# RL6845_IP_SVD register map
Vendor: Realtek
Registers are 32-bit, read-write, reset 0x0 unless marked. A register's access mark holds for its fields unless they carry their own. Offsets are from the block's base; [hi:lo] are bit positions; lines under a group give offsets from that group; {n}, {i} and the like mark numbered series; <NAME> marks a mode.

## lp_sys
Base 0x41008200
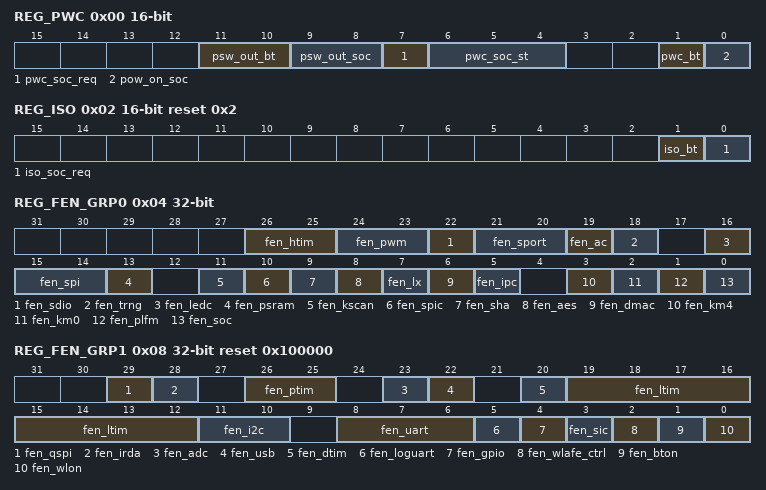
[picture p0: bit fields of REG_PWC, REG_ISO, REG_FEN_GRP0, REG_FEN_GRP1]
0x00 REG_PWC 16-bit access per field
  [11:10] psw_out_bt ro — BT domain power switch status 1: power on 0: power off Note:there are two group
  [9:8] psw_out_soc ro — SOC domain power switch status 1: power on 0: power off Note:there are two group
  [7] pwc_soc_req ro — pwc soc req arb result
  [6:4] pwc_soc_st ro — pwc soc arb result state
  [1] pwc_bt rw — This is BT function total power cut control 1: Enable BT power cut 0: Disable
  [0] pow_on_soc rw — 1:SYS PMC request to enable HP SOC power cut and diable ISO 0: SYS PMC request to disable HP SOC power cut and enable ISO
0x02 REG_ISO 16-bit access per field reset 0x2
  [1] iso_bt rw — 1: isolate signals from PD_LP_BT to other power domain 0: release iso
  [0] iso_soc_req ro — isolate signals from PD_HP_SOC to other power domain. It is arb result
0x04 REG_FEN_GRP0
  [26:25] fen_htim — 1: enable TIMER 14 function 0: disable
  [24:23] fen_pwm — 1: enable PWM TIMER function 0: disable [1]:pwm [0]:pulse
  [22] fen_sdio — 1: enable sdio device function 0: disable
  [21:20] fen_sport — 1: enable SPORT function 0: disable
  [19] fen_ac — 1: enable audio codec digital ip active function 0: disable
  [18] fen_trng — 1: enable TRNG function 0: disable
  [16] fen_ledc — 1: enable LEDC function 0: disable
  [15:14] fen_spi — 1: enable SPI1 function 0: disable
  [13] fen_psram — 1: enable PSRAM function 0: disable
  [11] fen_kscan — Flash kscan function enable 1: enable sce 0: disable
  [10] fen_spic — Flash spic function enable 1: enable flash 0: disable flash
  [9] fen_sha — 1: enable IPSEC SHA function 0: disable
  [8] fen_aes — 1: enable IPSEC AES function 0: disable
  [7] fen_lx — 1: enable LX1 system function 0: disable
  [6] fen_dmac — 1: enable GDMA function 0: disable
  [5] fen_ipc — 1: enable IPC function 0: reset
  [3] fen_km4 — 1: enable KM4 0: reset
  [2] fen_km0 — 1: enable KM0 0: reset
  [1] fen_plfm — 1: enable platform 0: reset
  [0] fen_soc — 1: enable hs soc sytem 0: disable hs soc system (Note: used as soc power on reset)
0x08 REG_FEN_GRP1 reset 0x100000
  [29] fen_qspi — 1: enable qspi function 0: disable
  [28] fen_irda — 1: enable irda function 0: disable
  [26:25] fen_ptim — pmc_timer function enable 1: enable 0: disable
  [23] fen_adc — lp adc function enable 1: enable 0: disable
  [22] fen_usb — usb core function enable 1: enable 0: disable
  [20] fen_dtim — Debug timer function enable 1: enable 0: disable
  [19:12] fen_ltim — Basic Timer0-7 function enable 1: enable 0: disable
  [11:10] fen_i2c — I2C1 function enable 1: enable 0: disable
  [8:6] fen_uart — Uart function enable (Note uart2 if for BT) 1: enable 0: disable
  [5] fen_loguart — Uartlog function enable 1: enable 0: disable
  [4] fen_gpio — SGPIO function enable 1: enable 0: disable
  [3] fen_sic — 1: enable SIC function 0: reset
  [2] fen_wlafe_ctrl — WL RFAFE control function enable 1: enable 0: disable
  [1] fen_bton — BTON function enable 1: enable 0: disable
  [0] fen_wlon — WLON function enable 1: enable 0: disable
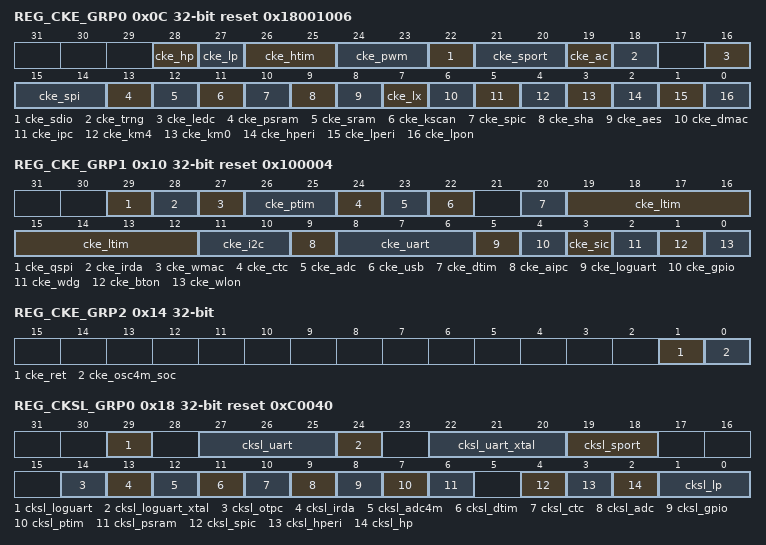
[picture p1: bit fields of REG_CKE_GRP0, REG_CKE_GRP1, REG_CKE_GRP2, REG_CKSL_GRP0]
0x0C REG_CKE_GRP0 reset 0x18001006
  [28] cke_hp — 1: Enable HP clock 0: Disable
  [27] cke_lp — 1: Enable LP clock 0: Disable
  [26:25] cke_htim — 1: Enable HS basic TIMER clock 0: Disable
  [24:23] cke_pwm — 1: Enable PWM TIMER clock 0: Disable [1] : pwm timer [0] : pulse timer
  [22] cke_sdio — 1: Enable sdio clock 0: Disable
  [21:20] cke_sport — 1: Enable sport1 clock 0: Disable
  [19] cke_ac — 1: Enable audio codec clock 0: Disable
  [18] cke_trng — 1: Enable trng bus clock 0: Disable
  [16] cke_ledc — 1: Enable ledc bus clock 0: Disable
  [15:14] cke_spi — 1: Enable SPI1 clock 0: Disable
  [13] cke_psram — 1: Enable PSRAM bus clock 0: Disable
  [12] cke_sram — 1: Enable hp sram clock 0: Disable
  [11] cke_kscan — 1: Enable kscan clock
  [10] cke_spic — 1: Enable SPIC source clock
  [9] cke_sha — 1: Enable ipsec SHA clock 0: Disable
  [8] cke_aes — 1: Enable ipsec AES clock 0: Disable
  [7] cke_lx — 1: Enable lx1 bus clock 0: Disable
  [6] cke_dmac — 1: Enable GDMA0 clock 0: Disable
  [5] cke_ipc — 1: Enable IPC clock 0: Disable
  [4] cke_km4 — 1: Enable hp KM4 clock 0: Disable
  [3] cke_km0 — 1: Enable lp KM0 clock 0: Disable
  [2] cke_hperi — 1: Enable peri_hclk clock all 0: Disable
  [1] cke_lperi — 1: Enable peri_lclk clock all 0: Disable
  [0] cke_lpon — 1.Enable lpon clk 0: Disable Note: this bit is controlled HW PMC, SW shall not modify
0x10 REG_CKE_GRP1 reset 0x100004
  [29] cke_qspi — 1: Enable qsip clock 0: Disable
  [28] cke_irda — 1: Enable irda clock 0: Disable
  [27] cke_wmac — 1: Enable WMAC AXI and AHB bus clock 0: Disable
  [26:25] cke_ptim — 1: Enable pmc timer clock 0: Disable
  [24] cke_ctc — 1: Enable Captouch clock 0: Disable
  [23] cke_adc — 1: Enable LS ADC clock 0: Disable
  [22] cke_usb — 1: Enable usb core clock 0: Disable
  [20] cke_dtim — 1: Enable LS dtim clk 0: Disable
  [19:12] cke_ltim — LS basic Timer0-7 clk enable 0: Disable
  [11:10] cke_i2c — 1: Enable HS I2C0 clock 0: Disable [1]: i2c1 [0]: i2c0
  [9] cke_aipc — 1: Enable aipc clock 0: Disable Note:HW has auto-gating function , sw needn't set it unless hw failed
  [8:6] cke_uart — 1: Enable Uart clock 0: Disable
  [5] cke_loguart — 1: Enable Uartlog clock 0: Disable
  [4] cke_gpio — 1: Enable GPIO clock 0: Disable
  [3] cke_sic — 1: Enable SIC clock 0: Disable
  [2] cke_wdg — 1: Enable wdg bus clock 0: Disable
  [1] cke_bton — 1: Enable BTON clock 0: Disable
  [0] cke_wlon — 1: Enable WLON clock 0: Disable
0x14 REG_CKE_GRP2
  [1] cke_ret — 1.Enable Some IP's clock who has retention function when pmc state change 0: Disable Note: this bit is controlled HW PMC, SW shall not modify
  [0] cke_osc4m_soc — 1.Enable 4M clk path for soc clk 0: Disable Note: this bit is controlled HW PMC, SW shall not modify
0x18 REG_CKSL_GRP0 reset 0xC0040
  [29] cksl_loguart — Select div_loguart's input clock (div_loguart's output clock is loguart trx clock ) 0: clock is xtal(source is dicided by cksl_loguart_xtal) 1: clock is osc4M
  [27:25] cksl_uart — Select div_uart[n]'s input clock (div_uart[n]'s output clock is uart[n] rx clock). (n=0,1,2) 0: clock is xtal(source is dicided by cksl_uart_xtal) 1: clock is osc4M
  [24] cksl_loguart_xtal — loguart_xtal clk select 0:clk_xtal_digi 1:clk_xtal_digi_div2
  [22:20] cksl_uart_xtal — uart xtal clk select, cksl_uart_xtal[n](n=0,1,2) 0: clk_xtal_digi 1:clk_xtal_digi_div2
  [19:18] cksl_sport — sport clock selection 0: equal to audio codec main clock (40M) 1: from cpu/dsp pll , after pll selection(cksl_i2s_pll)
  [14] cksl_otpc — otpc clock selection 0: osc4m 1: xtal40m Note: this bit will be set by pmc auto, when SW use otp, it must be set to 1 already
  [13] cksl_irda — IRDA clock selection 0: xtal 40m 1: pll divider out
  [12] cksl_adc4m — lp adc 4m clk selection 0: from osc4m 1: divider from xtal
  [11] cksl_dtim — dtim clock selection 0: xtal 1: 32k for sleep
  [10] cksl_ctc — CTC REG clock selection 0: lbus clock 1: ctc ip clock
  [9] cksl_adc — ADC INT clock selection 0: lbus clock 1: adc ip clock
  [8] cksl_gpio — GPIO INT clock selecton: 0: lbus clock 1: 32.768K clock from SDM
  [7] cksl_ptim — PMC Timer INT clock selecton: 0: lbus clock 1: 32.768K clock from SDM
  [6] cksl_psram — psram clock select 0: xtal 40m 1: pll divider out
  [4] cksl_spic — spic clock select 0: xtal 40m 1: pll divider out
  [3] cksl_hperi — hperi clock seletion 0: xtal 40m 1: pll divider out
  [2] cksl_hp — HP clock select,used for KM4 and sram 0: xtal 40m 1: pll divider out
  [1:0] cksl_lp — LP clock select, used for KM0 0: osc4m 1: xtal_40m 2: NotValid 3: pll divider out
0x1C REG_CKSL_GRP1
  [3:0] cksl_xtal — xtal selection, Default=40MHz No use,only support 40M
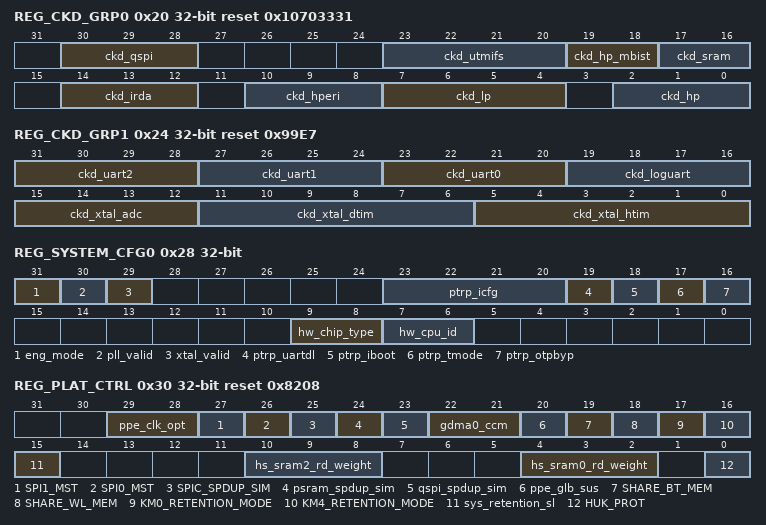
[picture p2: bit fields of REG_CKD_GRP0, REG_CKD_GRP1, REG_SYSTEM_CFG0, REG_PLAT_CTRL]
0x20 REG_CKD_GRP0 reset 0x10703331
  [30:28] ckd_qspi — qspi clock divider, it is based on pll 0: div1 1: div2 2: div3 3/other: divider by this value + 1
  [23:20] ckd_utmifs — usb full-speed 48M clock divider, it is based on cpu pll output 0: not valid 1: div2 2: div3 3/other: divider by this value + 1
  [19:18] ckd_hp_mbist — hp(km4) clock divider, it is based on pll 0: div1 1: div2 2: div3 3/other: divider by this value + 1 Note: this divider just for HW mbist test , SW don't use it
  [17:16] ckd_sram — sram clock divider, it is based on hp_clk 0: div1 1: div2 2: div3 3/other: divider by this value + 1
  [14:12] ckd_irda — irda clock divider, it is based on sys pll 0 : not valid 1: div2 2: div3 3/other: divider by this value + 1
  [10:8] ckd_hperi — peri_hclk clock divider, it is based on sys pll 0 : not valid 1: div2 2: div3 3/other: divider by this value + 1
  [7:4] ckd_lp — KM0 pll clock divider 0: div1 1: div2 2: div3 3/other: divider by this value + 1
  [2:0] ckd_hp — hp(km4) clock divider, it is based on pll 0: div1 1: div2 2: div3 3/other: divider by this value + 1
0x24 REG_CKD_GRP1 reset 0x99E7
  [31:28] ckd_uart2 — uart2 rx divider, source select by cksl_uart N:divider by N+1 1:divider by 2 0:divider by 1 Note: If uart need lps wake up when using xtal source , divider must set to 9 , and using xtal_20M input,when using OSC4M source , divider must set 1. (it is constrained by STA)
  [27:24] ckd_uart1 — uart1 rx divider, source select by cksl_uart N:divider by N+1 1:divider by 2 0:divider by 1 Note: If uart need lps wake up when using xtal source , divider must set to 9 , and using xtal_20M input,when using OSC4M source , divider must set 1. (it is constrained by STA)
  [23:20] ckd_uart0 — uart0 rx divider, source select by cksl_uart N:divider by N+1 1:divider by 2 0:divider by 1 Note: If uart need lps wake up when using xtal source , divider must set to 9 , and using xtal_20M input,when using OSC4M source , divider must set 1. (it is constrained by STA)
  [19:16] ckd_loguart — loguart rx divider, source select by cksl_uart N:divider by N+1 1:divider by 2 0:divider by 1 Note: If uart need lps wake up when using xtal source , divider must set to 9 , and using xtal_20M input,when using OSC4M source , divider must set 1. (it is constrained by STA)
  [15:12] ckd_xtal_adc — xtal 4m divider for adc Default is /10 which output 4M
  [11:6] ckd_xtal_dtim — xtal 1m divider for dtim Default is /40 which output 4M
  [5:0] ckd_xtal_htim — xtal 1m divider for htim Default is /40 which output 4M
0x28 REG_SYSTEM_CFG0 ro
  [31] eng_mode — Indicate PKG_ENG_SEL pad value 0: normal package; 1: engineering mode
  [30] pll_valid — Indicator pll is ready
  [29] xtal_valid — Indicator xtal 40M is ready
  [23:20] ptrp_icfg — Trapped ICFG data value 0: normall mode XXXX: the other mode (Test Mode)
  [19] ptrp_uartdl — Power on trapped uart download value 0: Normal boot 1: uartdownload boot TODO: it may be overwrited by efuse autoload
  [18] ptrp_iboot — Internal or external flash boot select
  [17] ptrp_tmode — 0: normal mode 1: test mode
  [16] ptrp_otpbyp — 1: force efuse autoload fail
  [9:8] hw_chip_type — Chip type 00: ASIC 01: FPGA 10: PALADIUM 11: RTL_SIM
  [7:6] hw_cpu_id — Different CPU reading this register will return different value. If read by KM0: return 0 If read by KM4: return 1 Other will return 2
0x30 REG_PLAT_CTRL reset 0x8208
  [29:28] ppe_clk_opt — 1X: always ON 01: always OFF 00: controlled by internal ICG
  [27] SPI1_MST — 1: SPI1 used as master 0: SPI1 used as slaver
  [26] SPI0_MST — 1: SPI0 used as master 0: SPI0 used as slaver
  [25] SPIC_SPDUP_SIM — 1: SPIC will wait 256 spic_clk cycles before ready 0: SPIC will wait 2^16 spic_clk cycles before ready
  [24] psram_spdup_sim — psramc simulatin speedup enable. Nouse because config form not specified .
  [23] qspi_spdup_sim — qspi simulation speedup enable
  [22:21] gdma0_ccm — GDMA0 clock control mode
  [20] ppe_glb_sus — Assert this bit to suspend PPE, active high
  [19] SHARE_BT_MEM — 1: Enable KM4 to share BT memory
  [18] SHARE_WL_MEM — 1: Enable KM4 to share WL memory
  [17] KM0_RETENTION_MODE — 1: Enable, when KM0 reset, cache will not be cleared 0: Disable, when KM0 reset, cache will be cleared by HW
  [16] KM4_RETENTION_MODE — 1: Enable, when KM4 reset, cache will not be cleared 0: Disable, when KM4 reset, cache will be cleared by HW
  [15] sys_retention_sl — S/L control signal to retention DFFs at PD_SOC, direct to SL pin, default 1 to prevent leakage 0: normal mode 1: retention data 1->0: restore data
  [10:8] hs_sram2_rd_weight — Excuted read command number continuously if both read and write command reached This is for bt/wl share_ram
  [4:2] hs_sram0_rd_weight — Excuted read command number continuously if both read and write command reached This is for hs_ram 512K
  [0] HUK_PROT — 0: only cpu can read HUK key 1: no one can read HUK key This bit will be latch to high when it was write to 1 until reset again .
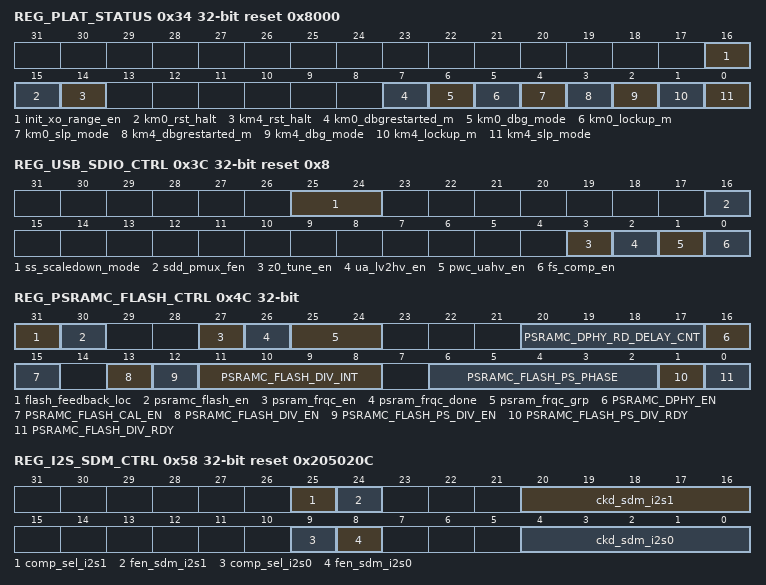
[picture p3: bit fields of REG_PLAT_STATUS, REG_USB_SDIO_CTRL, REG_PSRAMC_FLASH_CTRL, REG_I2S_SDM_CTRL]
0x34 REG_PLAT_STATUS access per field reset 0x8000
  [16] init_xo_range_en rw
  [15] km0_rst_halt rw
  [14] km4_rst_halt rw
  [7] km0_dbgrestarted_m ro — KM0 debug restart status
  [6] km0_dbg_mode ro — KM0 debug status
  [5] km0_lockup_m ro — KM0 lockup status
  [4] km0_slp_mode ro — KM0 sleep status
  [3] km4_dbgrestarted_m ro — KM4 debug restart status
  [2] km4_dbg_mode ro — KM4 halt status
  [1] km4_lockup_m ro — KM4 lockup status
  [0] km4_slp_mode ro — KM4 sleep status
0x3C REG_USB_SDIO_CTRL reset 0x8
  [25:24] ss_scaledown_mode — use scaled-down timing values for usb, resulting in faster simulations
  [16] sdd_pmux_fen — after sdio pinmux is configured, set this bit to 1
  [3] z0_tune_en — Zo_Tune , 45Ωauto calibration(Port-1 only) 0: Zo_Tune disable 1: Zo_Tune enable
  [2] ua_lv2hv_en — enable usb comparator l2h level shifter
  [1] pwc_uahv_en — enable usb comparator 3.3v power cut
  [0] fs_comp_en — enable usb full-speed differential comparator
0x40 REG_KM4_XO_CTRL0
  [31:0] init_xo_base
0x44 REG_KM4_XO_CTRL1
  [31:0] init_xo_top
0x4C REG_PSRAMC_FLASH_CTRL access per field
  [31] flash_feedback_loc rw — 0: pinmux S0 -> flash_spic, pinmux S1 -> psram_spic(if psramc_flash_en) 1: pinmux S1 -> flash_spic, pinmux S0 -> psram_spic(if psramc_flash_en)
  [30] psramc_flash_en rw — use psram_spic as flash controller, disable psram_phy
  [27] psram_frqc_en rw — enable psram auto freq change control flow
  [26] psram_frqc_done ro — indicate psram auto freq change is done
  [25:24] psram_frqc_grp rw — select psram auto freq change group
  [20:17] PSRAMC_DPHY_RD_DELAY_CNT rw — spic_dphy output dealy cnt, when set < 3, output data will occur at fourth or fifth axi clock from the rising edge of spi_rx_data_en; when set >= 3, data will occur after DPHY_RD_DELAY_CNT + 2 axi clock from the rising edge of spi_rx_data_en
  [16] PSRAMC_DPHY_EN rw — when set, enable spic_dphy function to read data from flash
  [15] PSRAMC_FLASH_CAL_EN rw — Flash calibration enable 1: delay flash sout for calibration 0: bypass flash sout to spic
  [13] PSRAMC_FLASH_DIV_EN rw — 1: enable to generate flash clock (no phase shift) divided by 600M pll clock, HW detect this signal's rising edge to start the no phase shift division circuit.
  [12] PSRAMC_FLASH_PS_DIV_EN rw — 1: enable to generate flash clock (with phase shift) divided by 600M pll clock, HW detect this signal's rising edge to start the phase shift clock division circuit.
  [11:8] PSRAMC_FLASH_DIV_INT rw — Flash clock division ratio, integrate part 0: divided by 1 1: divided by 2 2: divided by 3 3: divided by 4 .. 7: divided by 8 8: divided by 9 9: divided by 10 Note: SPI clock frequency is this divided clock/2
  [6:2] PSRAMC_FLASH_PS_PHASE rw — Flash clock phase shift in units of cpu/dsp pll clock cycles. If selected pll is 500MHz, the step is 2ns. 0: shift 0 step 1: shift 1 step ... 19: shift 19 step. Note, this value cannot be set more than FLASH_DIV_INT
  [1] PSRAMC_FLASH_PS_DIV_RDY ro — Ready flag of Flash clock with phase shift, Read only (input signal)
  [0] PSRAMC_FLASH_DIV_RDY ro — Ready flag of Flash clock, Read only (input signal)
0x50 REG_I2S0_COMP_STEP reset 0x19B4EC7
  [25:0] comp_step_i2s0 — i2s sdm clock interpolation period . This mains every this value's /N cycles , it will interpolate one /N+1 or /N-1 clock to compensate period error. For example to generate 45.1584M from pll 600M (max precsion is 0.1K, step bit must > 400M/0.1K) 1. set i2s0_sdm_ckd = 12 (N=13 , for 600M/13 = 46.xx M , 600/14 = 42.xx M) 2. Calcurate compensation normalized step : target_per = 1000/45.1584 = 22.14427ns base_per = 13000/600 = 21.66667ns intp_per = 14000/600 = 23.33333ns err_accu = |target_per - base_per| = 0.4776 err_comp = |target_per - intp_per| = 1.18906 normalizaiton = err_accu/err_comp = 0.401667..... Convert the decimal into hexadecimal. change format to unsigned Q0.26 , which is floo( normalizaion * (1<<26))
0x54 REG_I2S1_COMP_STEP reset 0x763D55
  [25:0] comp_step_i2s1 — i2s sdm clock interpolation period . This mains every this value's /N cycles , it will interpolate one /N+1 or /N-1 clock to compensate period error. For example to generate 98.304M from pll 600M 1. set i2s0_sdm_ckd = 5 (N=6 , for 600M/6 = 100M , 600/7 = 85.7 M) 2. Calcurate compensation normalized step : target_per = 1000/98.304 = 10.172526ns base_per = 6000/600 = 10ns intp_per = 7000/600 = 11.666667ns err_accu = |target_per - base_per| = 0.172526 err_comp = |target_per - intp_per| = 1.494141 if err_accu<err_comp normalizaiton = err_accu/err_comp = 0.11546835 else normalizaiton =err_comp/ err_accu , and modify comp_sel_i2s ,fen_sdm_i2s Convert the decimal into hexadecimal. change format to unsigned Q0.26 , which is floo( normalizaion * (1<<26))
0x58 REG_I2S_SDM_CTRL reset 0x205020C
  [25] comp_sel_i2s1 — Determine to select /N+1 or /N-1 clock when interpolation. when base_per is is closer to target_per ,please select 1. otherwise select 0. 0: select /(N-1) 1: select /(N+1)
  [24] fen_sdm_i2s1 — fen enable
  [20:16] ckd_sdm_i2s1 — Set a divider to nearest the target frequency . The i2s sdm base divider factor N is this value + 1
  [9] comp_sel_i2s0 — Determine to select /N+1 or /N-1 clock when interpolation. when base_per is is closer to target_per ,please select 1. otherwise select 0. 0: select /(N-1) 1: select /(N+1)
  [8] fen_sdm_i2s0 — fen enable
  [4:0] ckd_sdm_i2s0 — Set a divider to nearest the target frequency . The i2s sdm base divider factor N is this value + 1
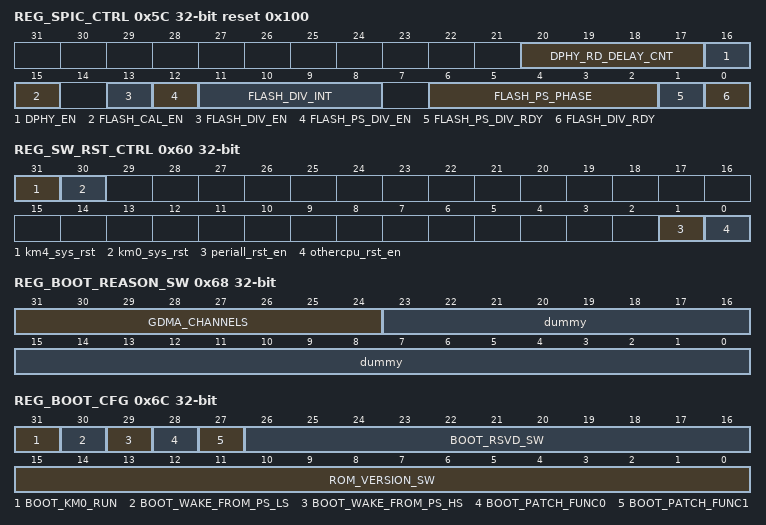
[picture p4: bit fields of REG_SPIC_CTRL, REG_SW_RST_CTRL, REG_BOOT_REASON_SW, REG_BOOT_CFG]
0x5C REG_SPIC_CTRL access per field reset 0x100
  [20:17] DPHY_RD_DELAY_CNT rw — spic_dphy output dealy cnt, when set < 3, output data will occur at fourth or fifth axi clock from the rising edge of spi_rx_data_en; when set >= 3, data will occur after DPHY_RD_DELAY_CNT + 2 axi clock from the rising edge of spi_rx_data_en
  [16] DPHY_EN rw — when set, enable spic_dphy function to read data from flash
  [15] FLASH_CAL_EN rw — Flash calibration enable 1: delay flash sout for calibration 0: bypass flash sout to spic
  [13] FLASH_DIV_EN rw — 1: enable to generate flash clock (no phase shift) divided by 400M pll clock, HW detect this signal's rising edge to start the no phase shift division circuit.
  [12] FLASH_PS_DIV_EN rw — 1: enable to generate flash clock (with phase shift) divided by 600M pll clock, HW detect this signal's rising edge to start the phase shift clock division circuit.
  [11:8] FLASH_DIV_INT rw — Flash clock division ratio, integrate part 0: not support 1: divided by 2 2: divided by 3 3: divided by 4 .. 7: divided by 8 8: divided by 9 9: divided by 10 Note: SPI clock frequency is this divided clock/2
  [6:2] FLASH_PS_PHASE rw — Flash clock phase shift in units of cpu/dsp pll clock cycles. If selected pll is 500MHz, the step is 2ns. 0: shift 0 step 1: shift 1 step ... 19: shift 19 step. Note, this value cannot be set more than FLASH_DIV_INT
  [1] FLASH_PS_DIV_RDY ro — Ready flag of Flash clock with phase shift, Read only (input signal)
  [0] FLASH_DIV_RDY ro — Ready flag of Flash clock, Read only (input signal)
0x60 REG_SW_RST_CTRL
  [31] km4_sys_rst — Only when REG_SW_RST_TRIG is 0x96969696 , this reg can be write
  [30] km0_sys_rst — Only when REG_SW_RST_TRIG is 0x96969696 , this reg can be write
  [1] periall_rst_en — 1. warm reset request by one cpu will reset all peri and local cpu 0. warm reset request by one cpu will only reset local cpu Note : peri rst will use sysrst mst also
  [0] othercpu_rst_en — 1. warm reset request by one cpu will reset other cpu's core and local cpu 0. warm reset request by one cpu will only reset local cpu
0x64 REG_SW_RST_TRIG
  [31:0] trig_rst — System reset trigger register Write 0x96969696 to enable the write of reset control Write 0x69696969 will trigger the system if REG_SW_RST_CTRL set .
0x68 REG_BOOT_REASON_SW
  [31:24] GDMA_CHANNELS — Indicate the usage status of every GDMA channel.
  [23:0] dummy
0x6C REG_BOOT_CFG
  [31] BOOT_KM0_RUN, [30] BOOT_WAKE_FROM_PS_LS, [29] BOOT_WAKE_FROM_PS_HS, [28] BOOT_PATCH_FUNC0, [27] BOOT_PATCH_FUNC1, [26:16] BOOT_RSVD_SW, [15:0] ROM_VERSION_SW
0x70 REG_SW_PATCH
  [31:0] sw_patch_saddr — SW patch code start addr. OTP physical addr 0x500-0x6FF will autoload to this addr .
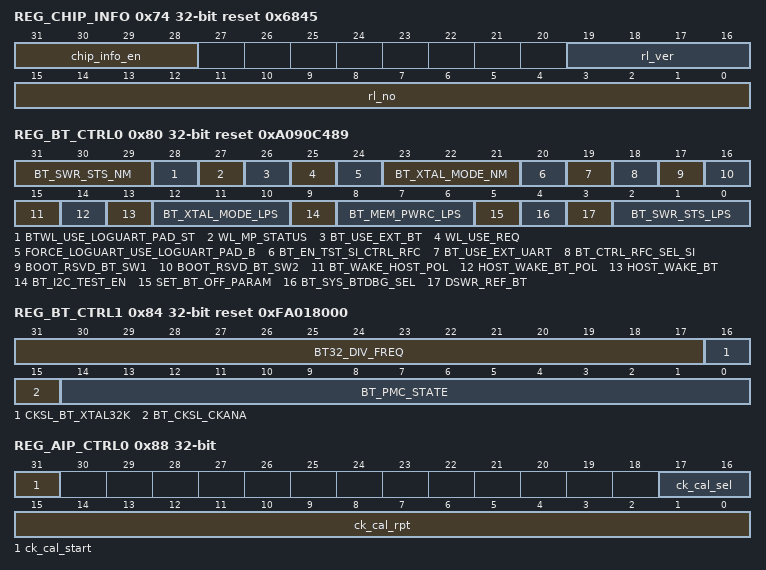
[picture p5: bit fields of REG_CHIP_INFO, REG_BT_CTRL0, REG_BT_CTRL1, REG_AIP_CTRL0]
0x74 REG_CHIP_INFO access per field reset 0x6845
  [31:28] chip_info_en rw — Enable Internal Chip Information display.(Don't move 0x74 address , for code is not auto-gen) 0xA: enable. Others: disable. Note: CHIP_INFO can be read only if CHIP_INFO_EN[3:0]=0xA, otherwise the read result will return 0x0.
  [19:16] rl_ver ro — CHIP cut verison : 0: A-cut 1: B-cut ...
  [15:0] rl_no ro — CHIP RL NUMBER : 0x6845
0x78 REG_BT_32K_CTRL0 reset 0x4C4B4
  [18:0] XTAL_CLK_FREQ_NM — used for BT 32K clock. indicate the frequence of XTAL Normal Mode, default is 312.5KHz
0x7C REG_BT_32K_CTRL1 reset 0x4C4B4
  [18:0] XTAL_CLK_FREQ_LPS — used for BT 32K clock. indicate the frequence of XTAL LPS Mode, default is 312.5KHz
0x80 REG_BT_CTRL0 access per field reset 0xA090C489
  [31:29] BT_SWR_STS_NM rw — SET SWR state when BT in active mode 000: RSVD 001: state1 0.7/PC/PFM 010: state2 0.8/PC/PFM 011: state3 0.9/PC/PFM 100: state4 0.9/SLP/PFM 101: state5 0.9/SLP/PWM 110: state6 0.9/NORM/PWM 111: state7 1.0/NORM/PWM
  [28] BTWL_USE_LOGUART_PAD_ST ro — The state of xor of WL_USE_REQ and BT_USE_REQ. 0: loguart use loguart trx pad 1: bt hci use loguart trx pad
  [27] WL_MP_STATUS rw — Wi-Fi MP status
  [26] BT_USE_EXT_BT rw — 1: select external BT 0: select internal BT
  [25] WL_USE_REQ rw — who uses loguart trx pad depends on the xor of WL_USE_REQ and BT_USE_REQ, wifi can send use request by change the value of WL_USE_REQ
  [24] FORCE_LOGUART_USE_LOGUART_PAD_B rw — Force wifi soc to use loguart pad mandatory if necessary 0: loguart use loguart trx pad 1: who uses loguart trx pad depends on BTWL_USE_LOGUART_PAD_ST
  [23:21] BT_XTAL_MODE_NM rw — SET XTAL state when BT in active mode 000: XTAL OFF 001: XTAL LPS, gating XTAL 40M 010: XTAL LPS, enable XTAL 40M 011: XTAL NM mode 100: XTAL HP mode
  [20] BT_EN_TST_SI_CTRL_RFC rw — 进入Test Mode 8 , 且同時 BT_EN_TST_SI_CTRL_RFC=1 , 才將RFC 端的SI 3 wire交由專線BT_SI_*_TST 控制; 若I2C 想要access RFC,设置BT_EN_TST_SI_CTRL_RFC=0 或者 將BT_SI_ENB_TST pull high(如果BT_SI_ENB_TST 有出 PIN)
  [19] BT_USE_EXT_UART rw — 1: BT use external uart 0: BT use internal uart
  [18] BT_CTRL_RFC_SEL_SI rw — Normal mode 或者Test Mode 2,通过此寄存器选择RFC的控制端. BT_CTRL_RFC_SEL_SI = 1,將RFC 端的SI 3 wire交由專線BT_SI_*_TST 控制;BT_CTRL_RFC_SEL_SI = 0,將RFC 端的SI 3 wire交由 I2C 控制. BT_CTRL_RFC_SEL_SI = 1时,也可通过将BT_SI_ENB_TST pull high,交由PI控制
  [17] BOOT_RSVD_BT_SW1 rw — RSVD for sotfware
  [16] BOOT_RSVD_BT_SW2 rw — RSVD for sotfware
  [15] BT_WAKE_HOST_POL rw — 1:BT_WAKE_HOST to CPU and pinmux 0:pinmux to CPU for external trig
  [14] HOST_WAKE_BT_POL rw — 1:HOST_WAKE_BT to BT and pinmux 0:pinmux to BT for external trig
  [13] HOST_WAKE_BT rw — CPU set this bit to 1 to wake BT
  [12:10] BT_XTAL_MODE_LPS rw — SET XTAL state when BT in LPS mode 000: XTAL OFF 001: XTAL LPS, gating XTAL 40M 010: XTAL LPS, enable XTAL 40M 011: XTAL NM mode 100: XTAL HP mode
  [9] BT_I2C_TEST_EN rw — SW control BT enter I2C test mode
  [8:6] BT_MEM_PWRC_LPS rw — BT DMEM/BFMEM power mode control in SLEEP. Setted before chip goes to SLEEP.Used to controll power mode of BT memory group when chip is in SLEEP. For FTC_ULP mem, pwr_lps[2:0] map to {SLP,RET,NAP}; For SNPS mem, pwr_lps[2:0] map to {SD,DS,LS}. 000 - active 001 - light sleep 010 - deep sleep 100 - shut down
  [5] SET_BT_OFF_PARAM rw — level -> pulse. Write to 1 to disable XTAL and SWR, before BT OFF. Before Write to 1 or after BT OFF,need to write to 0
  [4] BT_SYS_BTDBG_SEL rw — 0: select debug port from BTTOP 1: debug_port[31:18] from bt_misc; else from BTTOP
  [3] DSWR_REF_BT rw — core swr parameter refer BT status
  [2:0] BT_SWR_STS_LPS rw — SET SWR state when BT in LPS mode 000: RSVD 001: state1 0.7/PC/PFM 010: state2 0.8/PC/PFM 011: state3 0.9/PC/PFM 100: state4 0.9/SLP/PFM 101: state5 0.9/SLP/PWM 110: state6 0.9/NORM/PWM 111: state7 1.0/NORM/PWM
0x84 REG_BT_CTRL1 access per field reset 0xFA018000
  [31:17] BT32_DIV_FREQ rw — indicate the frequence of BT32K, default is 32KHz
  [16] CKSL_BT_XTAL32K rw — select BT 32K source 1: XTAL 0: OSC
  [15] BT_CKSL_CKANA rw — 1: enable osc4m when BT enter LPS 0: switch bt_ana_clk from osc4m to ana_100k when BT enter LPS
  [14:0] BT_PMC_STATE ro — indicate bt_misc PMC current state, for debug
0x88 REG_AIP_CTRL0 access per field
  [31] ck_cal_start rw — Start clk calibration . This bit will auto-set to 0 when cal done .
  [17:16] ck_cal_sel rw — Calibration clock selection . The refrence clock is xtal clock. 0: OSC4M 1: AON100K 2: AON128K for SDM
  [15:0] ck_cal_rpt ro — Clock calibration result
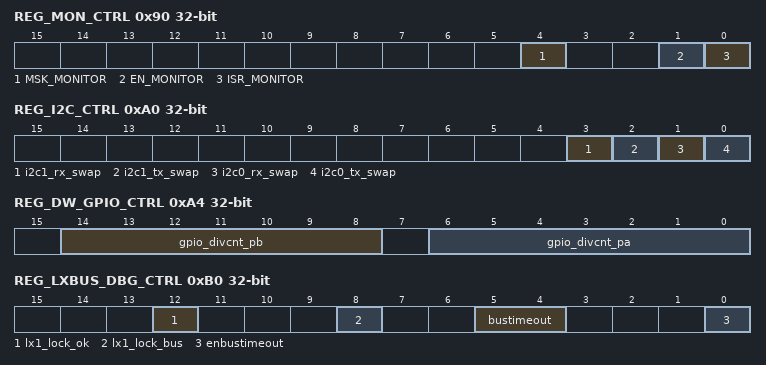
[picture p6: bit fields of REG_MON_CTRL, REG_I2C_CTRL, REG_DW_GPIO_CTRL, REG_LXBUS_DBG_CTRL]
0x90 REG_MON_CTRL access per field
  [4] MSK_MONITOR rw — ISR mask , if 1 , cpu will not receive interrup , although isr_monitor is assert
  [1] EN_MONITOR rw — Indicates whether enable the monitor function. When The monitor FIFO capture write event, it will trigger the sys illegal write interrupt, the interrupt source will auto clear when read out all the data~
  [0] ISR_MONITOR ro — Indicates the monitor FIFO has more
0x94 REG_MON_WREG0 ro
  [13:0] ILL_WADDR — Illegal write addr. every read ,it will update waddr and wdata
0x98 REG_MON_WREG1 ro
  [31:0] ILL_WDATA — Illegal write value
0xA0 REG_I2C_CTRL
  [3] i2c1_rx_swap — I2C1 RX swap control
  [2] i2c1_tx_swap — I2C1 TX swap control
  [1] i2c0_rx_swap — I2C0 RX swap control
  [0] i2c0_tx_swap — I2C0 TX swap control
0xA4 REG_DW_GPIO_CTRL
  [14:8] gpio_divcnt_pb — divider for dw gpiob debounce clk
  [6:0] gpio_divcnt_pa — divider for dw gpioa debounce clk
0xA8 REG_LXBUS_DBG0 ro
  [31:0] timeout_addr_mst — lx sys bus addr debug out
0xAC REG_LXBUS_DBG1 ro
  [31:0] timeout_addr_slv — lx sys bus addr debug out
0xB0 REG_LXBUS_DBG_CTRL access per field
  [12] lx1_lock_ok ro — lock lx1 bus lock ok
  [8] lx1_lock_bus rw — lock lx1 bus for debug
  [5:4] bustimeout rw — lx sys bus arb timeout thresh
  [0] enbustimeout rw — lx sys bus arb timeout enable
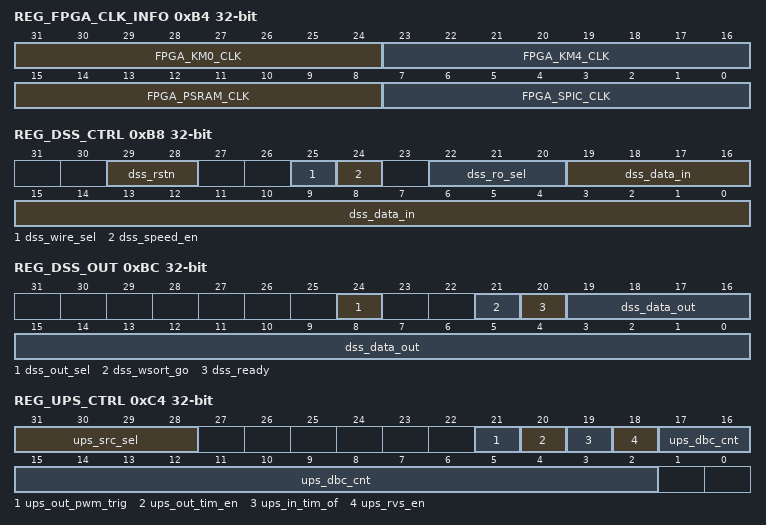
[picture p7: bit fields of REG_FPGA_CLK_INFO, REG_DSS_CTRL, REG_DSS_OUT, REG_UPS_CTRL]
0xB4 REG_FPGA_CLK_INFO ro
  [31:24] FPGA_KM0_CLK — FPGA KM0 clock
  [23:16] FPGA_KM4_CLK — FPGA KM4 clock
  [15:8] FPGA_PSRAM_CLK — FPGA PSRAM clock
  [7:0] FPGA_SPIC_CLK — FPGA SPIC clock
0xB8 REG_DSS_CTRL
  [29:28] dss_rstn, [25] dss_wire_sel, [24] dss_speed_en, [22:20] dss_ro_sel, [19:0] dss_data_in
0xBC REG_DSS_OUT access per field
  [24] dss_out_sel rw — 0: select lvt dss 1: select uhvt dss
  [21] dss_wsort_go ro
  [20] dss_ready ro
  [19:0] dss_data_out ro
0xC4 REG_UPS_CTRL
  [31:28] ups_src_sel — UPS trigger source select: 000: none 001: gpio trigger 010: comparator output 011: audio zcd_0 100: audio zcd_1 101: audio zcd_2
  [21] ups_out_pwm_trig — Enable for output trigger to pwm
  [20] ups_out_tim_en — Enable for output en signal to basic timer
  [19] ups_in_tim_of — Enable for basic timer overflow input
  [18] ups_rvs_en — Invert polarity for UPS input 0: posedge polarity 1: negedge polarity
  [17:2] ups_dbc_cnt — Debounce count for UPS funciton
0xCC REG_ECO_CTRL
  [31:0] dummy — HW used only, these are for reserved. ECO: dummy[0] means cksl_gpio4m, used to select u_mux_gpio; 1:osc_4m_lpon 0:sys_32k_lpon dummy[1], qspi using gdma, requested by SD 1: qspi using gdma with dma handshake signals 0: qspi using ppe with dma handshake signals dummy[2], set 1 when flash_spic feedback working at 1.8v dummy[3], set 1 when psram_spic(as flash controller) feedback working at 1.8v
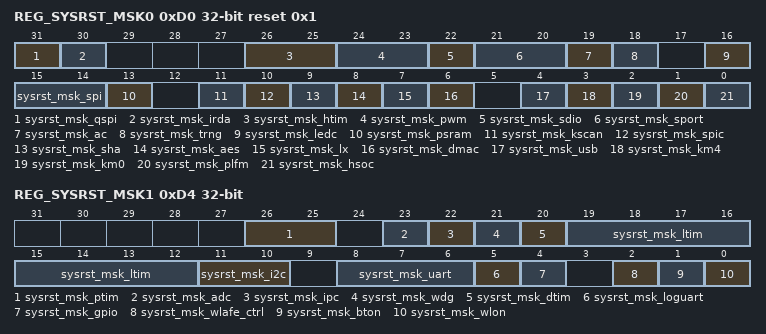
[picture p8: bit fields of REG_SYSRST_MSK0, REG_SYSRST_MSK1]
0xD0 REG_SYSRST_MSK0 reset 0x1
  [31] sysrst_msk_qspi — 1: mask qspi reset when sys reset happen 0: disable
  [30] sysrst_msk_irda — 1: mask irda reset when sys reset happen 0: disable
  [26:25] sysrst_msk_htim — 1: mask HP TIMER14 reset when sys reset happen 0: disable
  [24:23] sysrst_msk_pwm — 1: mask HP TIMER_PWM reset when sys reset happen 0: disable
  [22] sysrst_msk_sdio — 1: mask sdio reset when sys reset happen 0: disable
  [21:20] sysrst_msk_sport — 1: mask SPORT1 reset when sys reset happen 0: disable
  [19] sysrst_msk_ac — 1: mask audio codec active reset when sys reset happen 0: disable
  [18] sysrst_msk_trng — 1: mask TRNG reset when sys reset happen 0: disable
  [16] sysrst_msk_ledc — 1: mask LEDC reset when sys reset happen 0: disable
  [15:14] sysrst_msk_spi — 1: mask SPI1 reset when sys reset happen 0: disable
  [13] sysrst_msk_psram — 1: mask PSRAM reset when sys reset happen 0: disable
  [11] sysrst_msk_kscan — mask kscan when sys reset happen mask 1: mask 0: disable kscan
  [10] sysrst_msk_spic — mask Flash spic reset when sys reset happen mask 1: mask flash 0: disable flash
  [9] sysrst_msk_sha — 1: mask IPSEC SHA reset when sys reset happen 0: disable
  [8] sysrst_msk_aes — 1: mask IPSEC AES reset when sys reset happen 0: disable
  [7] sysrst_msk_lx — 1: mask LX reset when sys reset happen 0: disable
  [6] sysrst_msk_dmac — 1: mask GDMA reset when sys reset happen 0: disable
  [4] sysrst_msk_usb — 1: mask usb reset when sys reset happen 0: reset
  [3] sysrst_msk_km4 — 1: mask KM4 reset when sys reset happen 0: reset
  [2] sysrst_msk_km0 — 1: mask KM0 reset when sys reset happen 0: reset
  [1] sysrst_msk_plfm — 1: mask platform 0: reset
  [0] sysrst_msk_hsoc — 1: mask HP_SOC system reset when sys reset happen 0: reset
0xD4 REG_SYSRST_MSK1
  [26:25] sysrst_msk_ptim — 1: mask pmc timer reset when sys reset happen 0: disable
  [23] sysrst_msk_adc — 1: mask LS ADC reset when sys reset happen 0: reset
  [22] sysrst_msk_ipc — 1: mask IPC reset when sys reset happen 0: reset
  [21] sysrst_msk_wdg — 1: mask LS WDG 1~4 reset when sys reset happen 0: reset
  [20] sysrst_msk_dtim — 1: mask LP dtim reset when sys reset happen mask 0: reset
  [19:12] sysrst_msk_ltim — 1: mask LP basic TIMER0-7 reset when sys reset happen 0: disable
  [11:10] sysrst_msk_i2c — 1: mask HS I2C1 reset when sys reset happen 0: reset
  [8:6] sysrst_msk_uart — 1: mask UART reset when sys reset happen 0: disable
  [5] sysrst_msk_loguart — 1: mask LOGUART reset when sys reset happen 0: disable
  [4] sysrst_msk_gpio — 1: mask LS GPIO reset when sys reset happen 0: reset
  [2] sysrst_msk_wlafe_ctrl — 1: mask WL RFAFE control circuit, shall be 1 when mask WL or BT use WL RFAFE 0: reset
  [1] sysrst_msk_bton — mask BTON reset when sys reset happen 1: mask 0: disable
  [0] sysrst_msk_wlon — mask WLON reset when sys reset happen mask 1: mask 0: disable
0xF0 REG_FLASH_PARA_ADDR reset 0xBDC10512
  [31:0] dummy — HW used only , Used for access boundary check, SYSON is 512B which is 000-1FF.
0xF4 REG_DUMMY_090
  [31:0] dummy — HW used only , these are for reserved.
0xF8 REG_DUMMY_AIP_CTRL1 reset 0xF
  [7:0] aip_ctrl_rsvd1 — reserved for aip control
0xFC REG_DUMMY_AIP_INFO1 ro
  [7:0] aip_info_rsvd1 — reserved for aip info indication
